AUTOSAR XML (schema 4-3-0)
package /BMW/Platform/Stm/SwcImplementations
  swc implementation Stm_Implementation: behavior=Stm_InternalBehavior
    code-descriptors:
      code Code: artifact-descriptors=autosar-engineering-object={short-label=Default, category=SWSRC}
package /BMW/Platform/Stm/SwComponentTypes
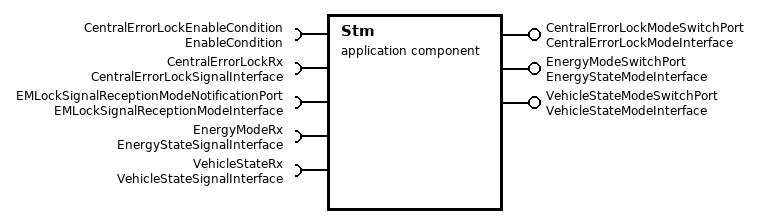
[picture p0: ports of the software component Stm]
  application sw component type Stm
    provide port CentralErrorLockModeSwitchPort: mode-switch-sender-com-spec{enhanced-mode-api=true, mode-group=currentCentralErrorLockMode, queue-length=1}, provided-interface=CentralErrorLockModeInterface
    provide port EnergyModeSwitchPort: mode-switch-sender-com-spec{enhanced-mode-api=true, mode-group=currentEnergyMode, queue-length=1}, provided-interface=EnergyStateModeInterface
    provide port VehicleStateModeSwitchPort: mode-switch-sender-com-spec{enhanced-mode-api=true, mode-group=currentVehicleStateMode, queue-length=1}, provided-interface=VehicleStateModeInterface
    5 x require port:
      CentralErrorLockEnableCondition: client-com-spec=SetEnableCondition, required-interface=EnableCondition
      CentralErrorLockRx: nonqueued-receiver-com-spec{data-element=centralErrorLock, alive-timeout=21, filter=data-filter-type=ALWAYS, init-value=3}, required-interface=CentralErrorLockSignalInterface
      EMLockSignalReceptionModeNotificationPort: required-interface=EMLockSignalReceptionModeInterface
      EnergyModeRx: nonqueued-receiver-com-spec{data-element=energyState, alive-timeout=21, filter=data-filter-type=ALWAYS, init-value=15}, required-interface=EnergyStateSignalInterface
      VehicleStateRx: nonqueued-receiver-com-spec{data-element=VehicleState, alive-timeout=0.5, filter=data-filter-type=ALWAYS, init-value=0}, required-interface=VehicleStateSignalInterface
    behavior Stm_InternalBehavior: data-type-mapping=[Stm_EnergyStateModeRequestTypeMap, Stm_EMLS_Mapping, Stm_CentralErrorLockModeRequestTypeMap, Stm_VehicleStatModeRequestTypeMap]
      exclusive area CentralErrorLockReadWrite_EA
      data receive error event DRET_Runnable_ErrorCentralErrorLock_CentralErrorLockRx_centralErrorLock: start-on-event=Runnable_ErrorCentralErrorLock, data=CentralErrorLockRx.centralErrorLock
      data receive error event DRET_Runnable_ErrorEnergyMode_EnergyModeRx_energyState: start-on-event=Runnable_ErrorEnergyMode, data=EnergyModeRx.energyState
      data receive error event DRET_Runnable_ErrorVehicleState_VehicleStateRx_VehicleState: start-on-event=Runnable_ErrorVehicleState, data=VehicleStateRx.VehicleState
      swc mode switch event MST_Runnable_InitialCELSupervision_0: start-on-event=Runnable_InitialCELSupervision, activation=ON-ENTRY, mode=EMLockSignalReceptionModeNotificationPort.currentEMLockSignalReceptionMode.EM_LOCK_RECEIVABLE
      data received event DRT_Runnable_ReceiveCentralErrorLock_CentralErrorLockRx_centralErrorLock: start-on-event=Runnable_ReceiveCentralErrorLock, data=CentralErrorLockRx.centralErrorLock
      data received event DRT_Runnable_ReceiveEnergyMode_EnergyModeRx_energyState: start-on-event=Runnable_ReceiveEnergyMode, data=EnergyModeRx.energyState
      data received event DRT_Runnable_ReceiveVehicleState_VehicleStateRx_VehicleState: start-on-event=Runnable_ReceiveVehicleState, data=VehicleStateRx.VehicleState
      swc mode switch event MST_Runnable_StopCentralErrorLockSupervision_0: start-on-event=Runnable_StopCentralErrorLockSupervision, activation=ON-ENTRY, mode=EMLockSignalReceptionModeNotificationPort.currentEMLockSignalReceptionMode.EM_LOCK_NOT_RECEIVABLE
      port-api-options:
        enable-take-address=false, error-handling=NO-TRANSFORMER-ERROR-HANDLING, indirect-api=false, port=CentralErrorLockEnableCondition
        enable-take-address=false, error-handling=NO-TRANSFORMER-ERROR-HANDLING, indirect-api=false, port=CentralErrorLockModeSwitchPort
        enable-take-address=false, error-handling=NO-TRANSFORMER-ERROR-HANDLING, indirect-api=false, port=CentralErrorLockRx
        enable-take-address=false, error-handling=NO-TRANSFORMER-ERROR-HANDLING, indirect-api=false, port=EMLockSignalReceptionModeNotificationPort
        enable-take-address=false, error-handling=NO-TRANSFORMER-ERROR-HANDLING, indirect-api=false, port=EnergyModeRx
        enable-take-address=false, error-handling=NO-TRANSFORMER-ERROR-HANDLING, indirect-api=false, port=EnergyModeSwitchPort
        enable-take-address=false, error-handling=NO-TRANSFORMER-ERROR-HANDLING, indirect-api=false, port=VehicleStateModeSwitchPort
        enable-take-address=false, error-handling=NO-TRANSFORMER-ERROR-HANDLING, indirect-api=false, port=VehicleStateRx
      8 x runnable:
        Runnable_ErrorCentralErrorLock: runs-inside-exclusive-area=CentralErrorLockReadWrite_EA, can-be-invoked-concurrently=true, mode-access-point=CentralErrorLockModeSwitchPort.currentCentralErrorLockMode, symbol=Stm_ErrorCentralErrorLock
          mode switch point SWITCH_CentralErrorLockModeSwitchPort_currentCentralErrorLockMode: mode-group=CentralErrorLockModeSwitchPort.currentCentralErrorLockMode
          sync call SC_CentralErrorLockEnableCondition_SetEnableCondition: operation=CentralErrorLockEnableCondition.SetEnableCondition, timeout=0
        Runnable_ErrorEnergyMode: can-be-invoked-concurrently=true, mode-access-point=EnergyModeSwitchPort.currentEnergyMode, symbol=Stm_ErrorEnergyMode
          mode switch point SWITCH_EnergyModeSwitchPort_currentEnergyMode: mode-group=EnergyModeSwitchPort.currentEnergyMode
        Runnable_ErrorVehicleState: can-be-invoked-concurrently=true, mode-access-point=VehicleStateModeSwitchPort.currentVehicleStateMode, symbol=Stm_ErrorVehicleState
          mode switch point SWITCH_VehicleStateModeSwitchPort_currentVehicleStateMode: mode-group=VehicleStateModeSwitchPort.currentVehicleStateMode
        Runnable_InitialCELSupervision: runs-inside-exclusive-area=CentralErrorLockReadWrite_EA, mode-access-point=CentralErrorLockModeSwitchPort.currentCentralErrorLockMode, symbol=Stm_InitialCentralErrorLockSupervision
          sync call SC_CentralErrorLockEnableCondition_SetEnableCondition: operation=CentralErrorLockEnableCondition.SetEnableCondition, timeout=0
        Runnable_ReceiveCentralErrorLock: runs-inside-exclusive-area=CentralErrorLockReadWrite_EA, can-be-invoked-concurrently=true, mode-access-point=CentralErrorLockModeSwitchPort.currentCentralErrorLockMode, symbol=Stm_ReceiveCentralErrorLock
          data-receive-point-by-arguments:
            access REC_CentralErrorLockRx_centralErrorLock: accessed-variable=CentralErrorLockRx.centralErrorLock
          mode switch point SWITCH_CentralErrorLockModeSwitchPort_currentCentralErrorLockMode: mode-group=CentralErrorLockModeSwitchPort.currentCentralErrorLockMode
          sync call SC_CentralErrorLockEnableCondition_SetEnableCondition: operation=CentralErrorLockEnableCondition.SetEnableCondition, timeout=0
        Runnable_ReceiveEnergyMode: can-be-invoked-concurrently=true, mode-access-point=EnergyModeSwitchPort.currentEnergyMode, symbol=Stm_ReceiveEnergyMode
          data-receive-point-by-arguments:
            access REC_EnergyModeRx_energyState: accessed-variable=EnergyModeRx.energyState
          mode switch point SWITCH_EnergyModeSwitchPort_currentEnergyMode: mode-group=EnergyModeSwitchPort.currentEnergyMode
        Runnable_ReceiveVehicleState: can-be-invoked-concurrently=true, mode-access-point=VehicleStateModeSwitchPort.currentVehicleStateMode, symbol=Stm_ReceiveVehicleState
          data-receive-point-by-arguments:
            access REC_VehicleStateRx_VehicleState: accessed-variable=VehicleStateRx.VehicleState
          mode switch point SWITCH_VehicleStateModeSwitchPort_currentVehicleStateMode: mode-group=VehicleStateModeSwitchPort.currentVehicleStateMode
        Runnable_StopCentralErrorLockSupervision: runs-inside-exclusive-area=CentralErrorLockReadWrite_EA, mode-access-point=CentralErrorLockModeSwitchPort.currentCentralErrorLockMode, symbol=Stm_StopCentralErrorLockSupervision
          mode switch point SWITCH_CentralErrorLockModeSwitchPort_currentCentralErrorLockMode: mode-group=CentralErrorLockModeSwitchPort.currentCentralErrorLockMode
          sync call SC_CentralErrorLockEnableCondition_SetEnableCondition: operation=CentralErrorLockEnableCondition.SetEnableCondition, timeout=0
